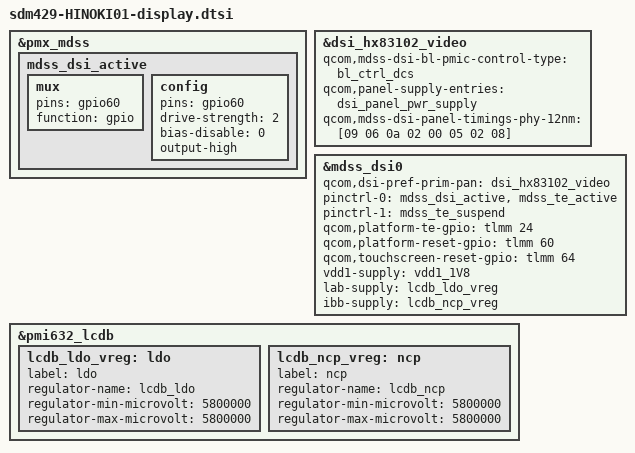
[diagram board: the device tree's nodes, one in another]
/*
 * This software is contributed or developed by KYOCERA Corporation.
 * (C) 2019 KYOCERA Corporation
 *
 * This program is free software; you can redistribute it and/or modify
 * it under the terms of the GNU General Public License version 2 and
 * only version 2 as published by the Free Software Foundation.
 *
 * This program is distributed in the hope that it will be useful,
 * but WITHOUT ANY WARRANTY; without even the implied warranty of
 * MERCHANTABILITY or FITNESS FOR A PARTICULAR PURPOSE.  See the
 * GNU General Public License for more details.
 */

#include "sdm439-mtp.dtsi"

#include "dsi-panel-kc-lce-hx83102b-video.dtsi"

&pmx_mdss {
	mdss_dsi_active: mdss_dsi_active {
		mux {
			pins = "gpio60";
			function = "gpio";
		};

		config {
			pins = "gpio60";
			drive-strength = <2>; /* 2 mA */
			bias-disable = <0>; /* no pull */
			output-high;
		};
	};
};

&dsi_hx83102_video {
	/*qcom,mdss-dsi-bl-pmic-control-type = "bl_ctrl_pwm";
	qcom,mdss-dsi-bl-pmic-pwm-frequency = <100>;
	qcom,mdss-dsi-bl-pmic-bank-select = <0>;
	qcom,mdss-dsi-pwm-gpio = <&pm8953_gpios 8 0>;*/
	qcom,mdss-dsi-bl-pmic-control-type = "bl_ctrl_dcs";
	qcom,panel-supply-entries = <&dsi_panel_pwr_supply>;
	/delete-property/ qcom,mdss-dsi-panel-timings;
	qcom,mdss-dsi-panel-timings-phy-12nm = [09 06 0a 02 00 05 02 08];
};

&mdss_dsi0 {
	/delete-property/ vdd-supply;
	/delete-property/ vddio-supply;
	qcom,dsi-pref-prim-pan = <&dsi_hx83102_video>;
	pinctrl-names = "mdss_default", "mdss_sleep";
 	pinctrl-0 = <&mdss_dsi_active &mdss_te_active>;
	pinctrl-1 = <&mdss_te_suspend>;

	qcom,platform-te-gpio = <&tlmm 24 0>;
	qcom,platform-reset-gpio = <&tlmm 60 0>;
	qcom,touchscreen-reset-gpio = <&tlmm 64 0>;
	vdd1-supply = <&vdd1_1V8>;
	lab-supply = <&lcdb_ldo_vreg>;
	ibb-supply = <&lcdb_ncp_vreg>;
};

&pmi632_lcdb{
	lcdb_ldo_vreg: ldo {
		label = "ldo";
		regulator-name = "lcdb_ldo";
		regulator-min-microvolt = <5800000>;
		regulator-max-microvolt = <5800000>;
	};

	lcdb_ncp_vreg: ncp {
		label = "ncp";
		regulator-name = "lcdb_ncp";
		regulator-min-microvolt = <5800000>;
		regulator-max-microvolt = <5800000>;
	};
};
